# STM32F030xC register map
File version: 1.0
Registers are 32-bit, read-write, reset 0x0 unless marked. A register's access mark holds for its fields unless they carry their own. Offsets are from the block's base; [hi:lo] are bit positions; {n}, {i} and the like mark numbered series.

## PWR — Power Control
Base 0x40007000
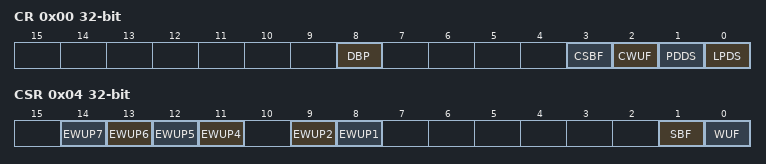
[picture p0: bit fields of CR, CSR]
0x00 CR — PWR power control register
  [8] DBP — Disable Backup Domain write protection
  [3] CSBF — Clear Standby Flag
  [2] CWUF — Clear Wakeup Flag
  [1] PDDS — Power Down Deepsleep
  [0] LPDS — Low-power Deepsleep
    0=MAIN (Voltage Regulator in main mode during deepsleep mode); 1=LOW_POWER (Voltage Regulator in low-power mode during deepsleep mode)
0x04 CSR — PWR power control/status register
  [n+7] EWUP{n} (n=4..7) — Enable WKUP pin {n}
  [9] EWUP2 — Enable WKUP pin 2
  [8] EWUP1 — Enable WKUP pin 1
  [1] SBF — Standby Flag
  [0] WUF — Wakeup Flag

## SYSCFG — SysTem Configuration
Base 0x40010000
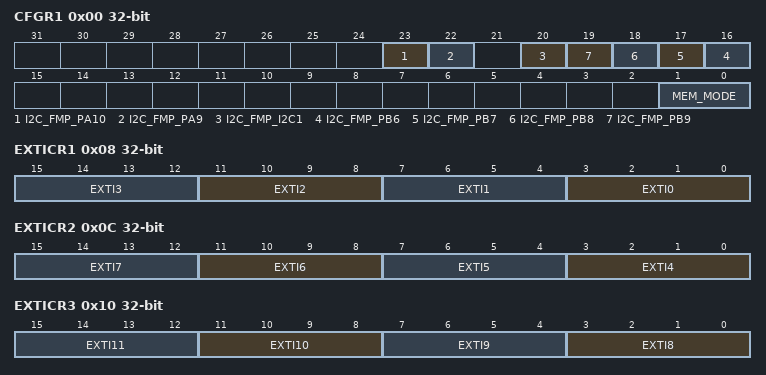
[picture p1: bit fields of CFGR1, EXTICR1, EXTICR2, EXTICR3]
0x00 CFGR1 — SYSCFG configuration register 1
  [23] I2C_FMP_PA10 — Enable Fast Mode Plus on PA10
  [22] I2C_FMP_PA9 — Enable Fast Mode Plus on PA9
  [20] I2C_FMP_I2C1 — Enable Fast Mode Plus on PB10, PB11, PF6 and PF7
  [n+10] I2C_FMP_PB{n} (n=6..9) — I2C PB{n} Fast mode plus
  [1:0] MEM_MODE — SYSCFG_Memory Remap Config
    0=FLASH (Main Flash memory mapped at 0x00000000); 1=SYSTEMFLASH (System Flash memory mapped at 0x00000000); 3=SRAM (Embedded SRAM mapped at 0x00000000)
0x08 EXTICR1 — SYSCFG external interrupt configuration register
  [4n+3:4n] EXTI{n} (n=0..3) — EXTI {n} configuration
0x0C EXTICR2 — SYSCFG external interrupt configuration register
  [4n-13:4n-16] EXTI{n} (n=4..7) — EXTI {n} configuration
0x10 EXTICR3 — SYSCFG external interrupt configuration register
  [4n-29:4n-32] EXTI{n} (n=8..11) — EXTI {n} configuration
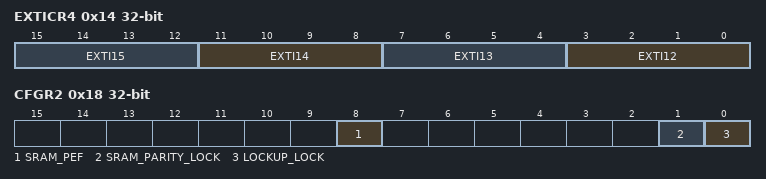
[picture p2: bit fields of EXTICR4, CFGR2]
0x14 EXTICR4 — SYSCFG external interrupt configuration register
  [4n-45:4n-48] EXTI{n} (n=12..15) — EXTI {n} configuration
0x18 CFGR2 — SYSCFG configuration register 2
  [8] SRAM_PEF — SRAM Parity error flag
  [1] SRAM_PARITY_LOCK — Enables and locks the SRAM_PARITY error signal with Break Input of TIMER1
  [0] LOCKUP_LOCK — Enables and locks the LOCKUP (Hardfault) output of CortexM0 with Break Input of TIMER1

## EXTI — External Interrupt/Event Controller
Base 0x40010400
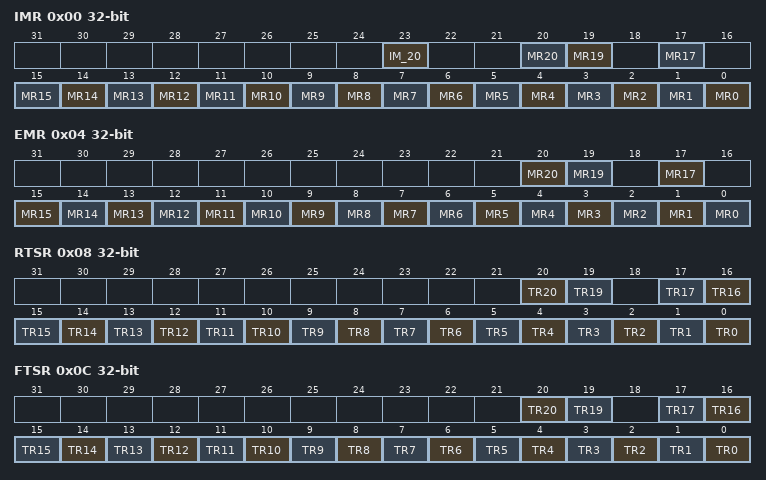
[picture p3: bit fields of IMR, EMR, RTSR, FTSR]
0x00 IMR — EXTI Interrupt mask register
  [23] IM_20 — Interrupt Mask All
  [20] MR20 — Interrupt Mask on line 20
  [19] MR19 — Interrupt Mask on line 19
  [17] MR17 — Interrupt Mask on line 17
  [n] MR{n} (n=0..15) — Interrupt Mask on line {n}
0x04 EMR — EXTI Event mask register
  [20] MR20 — Event Mask on line 20
  [19] MR19 — Event Mask on line 19
  [17] MR17 — Event Mask on line 17
  [n] MR{n} (n=0..15) — Event Mask on line {n}
0x08 RTSR — EXTI Rising trigger selection register
  [20] TR20 — Rising trigger event configuration bit of line 20
  [19] TR19 — Rising trigger event configuration bit of line 19
  [n] TR{n} (n=0..17) — Rising trigger event configuration bit of line {n}
0x0C FTSR — EXTI Falling trigger selection register
  [20] TR20 — Falling trigger event configuration bit of line 20
  [19] TR19 — Falling trigger event configuration bit of line 19
  [n] TR{n} (n=0..17) — Falling trigger event configuration bit of line {n}
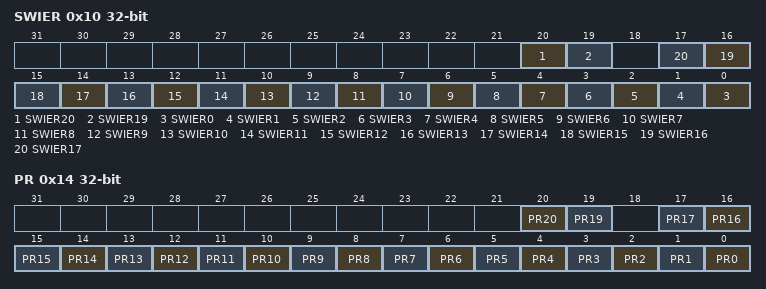
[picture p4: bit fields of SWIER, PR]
0x10 SWIER — EXTI Software interrupt event register
  [20] SWIER20 — Software Interrupt on line 20
  [19] SWIER19 — Software Interrupt on line 19
  [n] SWIER{n} (n=0..17) — Software Interrupt on line {n}
0x14 PR — EXTI Pending register
  [20] PR20 — Pending bit 20
  [19] PR19 — Pending bit 19
  [n] PR{n} (n=0..17) — Pending bit {n}

## ADC
Base 0x40012708
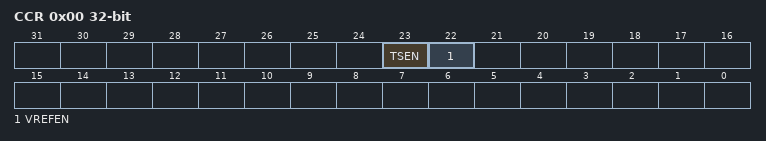
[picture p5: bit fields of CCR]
0x00 CCR — ADC common configuration register
  [23] TSEN — ADC internal path to temperature sensor enable
  [22] VREFEN — ADC internal path to VrefInt enable

## DBGMCU — Debug MCU
Base 0x40015800
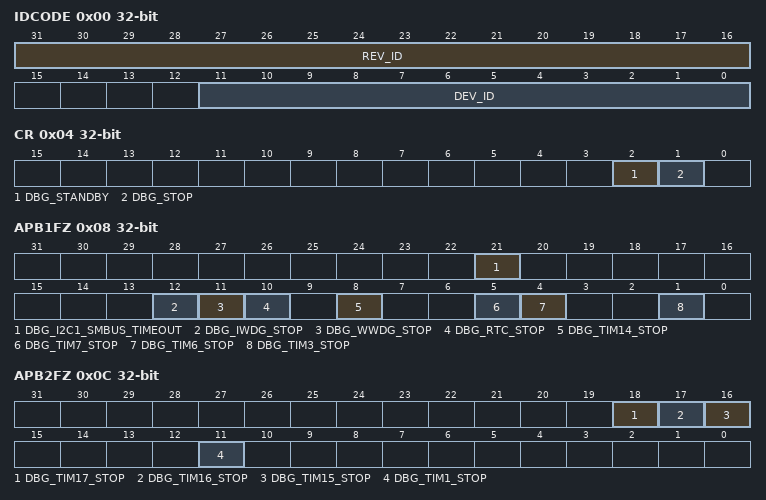
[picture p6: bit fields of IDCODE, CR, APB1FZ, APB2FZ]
0x00 IDCODE — MCU device ID code
  [31:16] REV_ID — REV_ID[15:0] bits (Revision Identifier)
  [11:0] DEV_ID — Device Identifier
0x04 CR — Debug MCU configuration register
  [2] DBG_STANDBY — Debug Standby mode
  [1] DBG_STOP — Debug Stop Mode
0x08 APB1FZ — Debug MCU APB1 freeze register
  [21] DBG_I2C1_SMBUS_TIMEOUT — I2C1 SMBUS timeout mode stopped when Core is halted
  [12] DBG_IWDG_STOP — Debug Independent Watchdog stopped when Core is halted
  [11] DBG_WWDG_STOP — Debug Window Watchdog stopped when Core is halted
  [10] DBG_RTC_STOP — RTC Calendar frozen when core is halted
  [8] DBG_TIM14_STOP — TIM14 counter stopped when core is halted
  [5] DBG_TIM7_STOP — TIM7 counter stopped when core is halted
  [4] DBG_TIM6_STOP — TIM6 counter stopped when core is halted
  [1] DBG_TIM3_STOP — TIM3 counter stopped when core is halted
0x0C APB2FZ — Debug MCU APB2 freeze register
  [18] DBG_TIM17_STOP — TIM17 counter stopped when core is halted
  [17] DBG_TIM16_STOP — TIM16 counter stopped when core is halted
  [16] DBG_TIM15_STOP — TIM15 counter stopped when core is halted
  [11] DBG_TIM1_STOP — TIM1 counter stopped when core is halted

## FLASH — FLASH Registers
Base 0x40022000
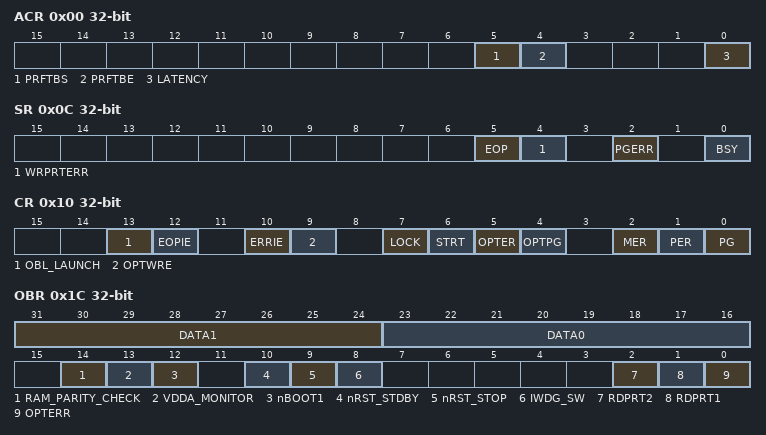
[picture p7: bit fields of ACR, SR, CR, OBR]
0x00 ACR — FLASH access control register
  [5] PRFTBS — Prefetch Buffer Status
  [4] PRFTBE — Prefetch Buffer Enable
  [0] LATENCY — LATENCY bit (Latency)
    0=FLASH Zero Latency cycle; 1=FLASH One Latency cycle
0x04 KEYR — FLASH key register
  [31:0] FKEYR — FPEC Key
0x08 OPTKEYR — FLASH OPT key register
  [31:0] OPTKEYR — Option Byte Key
0x0C SR — FLASH status register
  [5] EOP — End of operation
  [4] WRPRTERR — Write Protection Error
  [2] PGERR — Programming Error
  [0] BSY — Busy
0x10 CR — FLASH control register
  [13] OBL_LAUNCH — Option Bytes Loader Launch
  [12] EOPIE — End of operation interrupt enable
  [10] ERRIE — Error Interrupt Enable
  [9] OPTWRE — Option Bytes Write Enable
  [7] LOCK
  [6] STRT — Start
  [5] OPTER — Option Byte Erase
  [4] OPTPG — Option Byte Programming
  [2] MER — Mass Erase
  [1] PER — Page Erase
  [0] PG — Programming
0x14 AR — FLASH address register
  [31:0] FAR — Flash Address
0x1C OBR — FLASH option bytes register
  [31:24] DATA1
  [23:16] DATA0
  [14] RAM_PARITY_CHECK
  [13] VDDA_MONITOR — VDDA power supply supervisor
  [12] nBOOT1
  [10] nRST_STDBY
  [9] nRST_STOP
  [8] IWDG_SW
  [2] RDPRT2 — Read protection Level 2
  [1] RDPRT1 — Read protection Level 1
  [0] OPTERR — Option Byte Error
0x20 WRPR — FLASH option bytes register
  [15:0] WRP — Write Protect

## CRC — CRC calculation unit
Base 0x40023000
0x00 DR — CRC Data register
  [31:0] DR — Data register bits
0x04 IDR 8-bit — CRC Independent data register
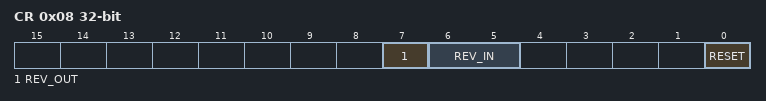
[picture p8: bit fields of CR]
0x08 CR — CRC Control register
  [7] REV_OUT — REV_OUT Reverse Output Data bits
    0=NONE (Output Data bit order not affected); 1=BIT (Output Data bit reversal done by bit)
  [6:5] REV_IN — REV_IN Reverse Input Data bits
    0=NONE (Input Data bit order not affected); 1=BYTE (Input Data bit reversal done by byte); 2=HALFWORD (Input Data bit reversal done by half-word); 3=WORD (Input Data bit reversal done by word)
  [0] RESET — RESET the CRC computation unit bit
0x10 INIT — Initial CRC value register
  [31:0] INIT — Initial CRC value bits

## GPIOA — General Purpose I/O
Base 0x48000000
Same registers: GPIOB 0x48000400, GPIOC 0x48000800, GPIOD 0x48000C00, GPIOF 0x48001400
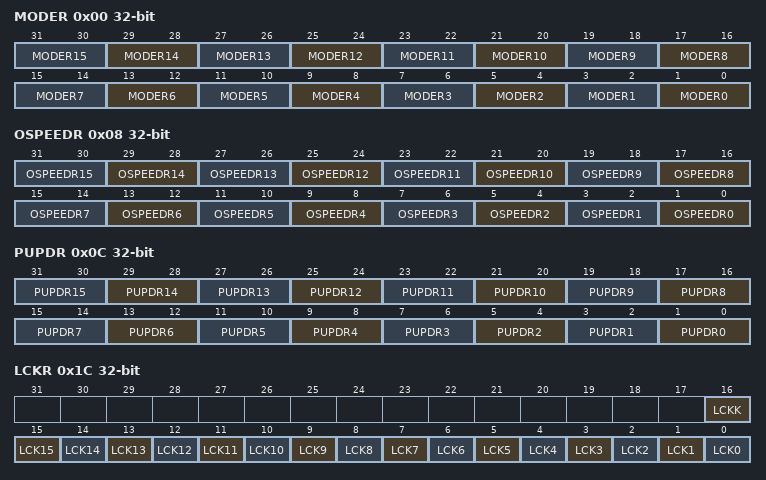
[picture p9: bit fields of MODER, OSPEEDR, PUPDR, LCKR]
0x00 MODER — GPIO port mode register
  [2n+1:2n] MODER{n} (n=0..15)
0x04 OTYPER — GPIO port output type register
0x08 OSPEEDR — GPIO port output speed register
  [2n+1:2n] OSPEEDR{n} (n=0..15)
0x0C PUPDR — GPIO port pull-up/pull-down register
  [2n+1:2n] PUPDR{n} (n=0..15)
0x10 IDR — GPIO port input data register
0x14 ODR — GPIO port output data register
0x18 BSRR — GPIO port bit set/reset register
0x1C LCKR — GPIO port configuration lock register
  [16] LCKK, [n] LCK{n} (n=0..15)
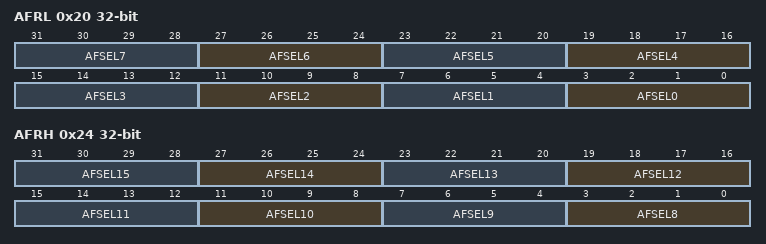
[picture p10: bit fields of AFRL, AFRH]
0x20 AFRL — GPIO alternate function low register
  [4n+3:4n] AFSEL{n} (n=0..7)
0x24 AFRH — GPIO alternate function low register
  [4n-29:4n-32] AFSEL{n} (n=8..15)
0x28 BRR — GPIO bit reset register
